# NANO103AE_v1 register map
File version: 1.0
Registers are 32-bit, read-write, reset 0x0 unless marked. A register's access mark holds for its fields unless they carry their own. Offsets are from the block's base; [hi:lo] are bit positions; {n}, {i} and the like mark numbered series.

## UART0 — UART Register Map
Base 0x40050000
Same registers: UART1 0x40150000
0x00 UART_DAT ro reset not defined — UART Receive/Transmit Buffer Register.
  [7:0] DAT — Receive /Transmit Buffer. Write Operation: By writing one byte to this register, the data byte will be stored in transmitter FIFO. The UART Controller will send out the data stored in transmitter FIFO top location through the UART_DAT. Read Operation: By reading this register, the UART will return an 8-bit data received from receiving FIFO.
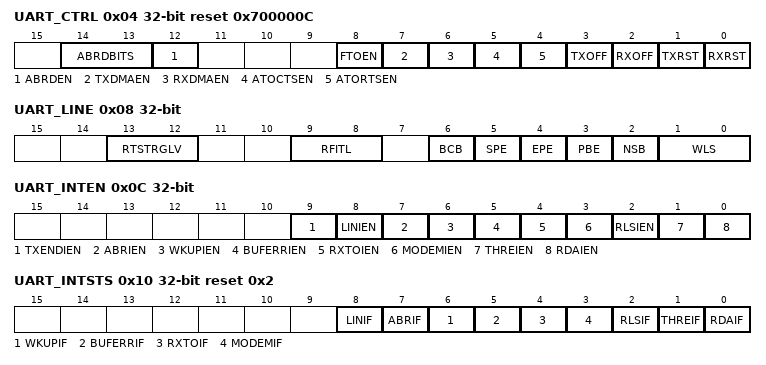
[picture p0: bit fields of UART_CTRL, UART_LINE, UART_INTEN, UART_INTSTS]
0x04 UART_CTRL reset 0x700000C — UART Control Register.
  [14:13] ABRDBITS — Auto-baud Rate Detect Bit Length. Note: The calculation of bit number includes the START bit.
    0=1-bit time from Start bit to the 1st rising edge. The input pattern shall be 0x01; 1=2-bit time from Start bit to the 1st rising edge. The input pattern shall be 0x02; 2=4-bit time from Start bit to the 1st rising edge. The input pattern shall be 0x08; 3=8-bit time from Start bit to the 1st rising edge. The input pattern shall be 0x80
  [12] ABRDEN — Auto-baud Rate Detect EnableBit. Note: When the auto-baud rate detect operation finishes, hardware will clear this bit and the associated interrupt (ABRIF) will be generated (If ABRIEN (UART_INTEN [7]) be enabled).
    0=Auto-baud rate detect function Disabled; 1=Auto-baud rate detect function Enabled
  [8] FTOEN — Frame Time Out Enable Bit. This bit is used to enable the timer counter even the FIFO is still empty.
    0=Frame time out Disabled; 1=Frame time out Enabled
  [7] TXDMAEN — TX DMA Enable Bit. This bit can enable or disable TX DMA service.
    0=TX DMA Disabled; 1=TX DMA Enabled
  [6] RXDMAEN — RX DMA Enable Bit. This bit can enable or disable RX DMA service.
    0=RX DMA Disabled; 1=RX DMA Enabled
  [5] ATOCTSEN — nCTS Auto-flow Control Enable Bit. Note:When nCTS auto-flow is enabled, the UART will send data to external device if nCTS input assert (UART will not send data to device until nCTS is asserted).
    0=nCTS auto-flow control Disabled; 1=nCTS auto-flow control Enabled
  [4] ATORTSEN — nRTS Auto-flow Control Enable Bit. Note: When nRTS auto-flow is enabled, if the number of bytes in the RX FIFO equals the RTSTRGLV (UART_LINE[13:12]), the UART will de-assert nRTS signal.
    0=nRTS auto-flow control Disabled; 1=nRTS auto-flow control Enabled
  [3] TXOFF — Transfer Disable Bit
    0=Transfer Enabled; 1=Transfer Disabled
  [2] RXOFF — Receiver Disable Bit. Note1:In RS-485 NMM mode, user can set this bit to receive data before detecting address byte. Note2: In RS-485 AAD mode, this bit will be setting to "1" automatically. Note3: In RS-485 AUD mode and LIN "break + sync +PID" header mode, hardware will control data automatically, so don't fill any value to this bit.
    0=Receiver Enabled; 1=Receiver Disabled
  [1] TXRST — TX Field Software Reset. When TXRST (UART_CTRL[1]) is set, all the byte in the transmit FIFO and TX internal state machine are cleared. Note: This bit will automatically clear at least 3 UART peripheral clock cycles
    0=No effect; 1=Reset the TX internal state machine and pointers
  [0] RXRST — RX Field Software Reset. When RXRST (UART_CTRL[0]) is set, all the byte in the receiver FIFO and RX internal state machine are cleared. Note: This bit will automatically clear at least 3 UART peripheral clock cycles.
    0=No effect; 1=Reset the RX internal state machine and pointers
0x08 UART_LINE — UART Transfer Line Control Register.
  [13:12] RTSTRGLV — nRTS Trigger Level for Auto-flow Control Use. Note: This field is used for auto nRTS flow control.
    0=nRTS Trigger Level is 1 byte; 1=nRTS Trigger Level is 4 bytes; 2=nRTS Trigger Level is 8 bytes; 3=nRTS Trigger Level is 14 bytes
  [9:8] RFITL — RX FIFO Interrupt Trigger Level. When the number of bytes in the receive FIFO equals the RFITL, the RDAIF will be set (if RDAIEN (UART_INTEN [0]) enabled, and an interrupt will be generated). Note: When operating in IrDA mode or RS-485 mode, the RFITL must be set to "0".
    0=RX FIFO Interrupt Trigger Level is 1 byte; 1=RX FIFO Interrupt Trigger Level is 4 bytes; 2=RX FIFO Interrupt Trigger Level is 8 bytes; 3=RX FIFO Interrupt Trigger Level is 14 bytes
  [6] BCB — Break Control Bit. Note: When this bit is set to logic 1, the serial data output (TX) is forced to the Spacing State (logic 0). This bit acts only on TX line and has no effect on the transmitter logic.
    0=Break Control Disabled; 1=Break Control Enabled
  [5] SPE — Stick Parity Enable Bit. Note: If PBE (UART_LINE[3]) and EPE (UART_LINE[4]) are logic 1, the parity bit is transmitted and checked as logic 0. If PBE (UART_LINE[3]) is 1 and EPE (UART_LINE[4]) is 0 then the parity bit is transmitted and checked as 1.
    0=Stick parity Disabled; 1=Stick parity Enabled
  [4] EPE — Even Parity EnableBit. Note:This bit has effect only when PBE (UART_LINE[3]) is set.
    0=Odd number of logic 1's is transmitted and checked in each word; 1=Even number of logic 1's is transmitted and checked in each word
  [3] PBE — Parity Bit EnableBit. Note: Parity bit is generated on each outgoing character and is checked on each incoming data.
    0=No parity bit generated Disabled; 1=Parity bit generated Enabled
  [2] NSB — Number of "STOP Bit"
    0=One "STOP bit" is generated in the transmitted data; 1=When select 5-bit word length, 1.5 "STOP bit" is generated in the transmitted data. When select 6-, 7- and 8-bit word length, 2 "STOP bit" is generated in the transmitted data
  [1:0] WLS — Word Length Selection. This field sets UART word length.
    {v}={v+5} bits (v=0..3)
0x0C UART_INTEN — UART Interrupt Enable Register.
  [9] TXENDIEN — Transmitter Empty FInterrupt Enable Bit. Note: If the bit is enabled, there is interrupt event when the TXENDF (UART_FIFOSTS[11]) is actived.
    0=Transmit Empty interrupt Disabled; 1=Transmit Empty interrupt Enabled
  [8] LINIEN — LIN Bus Interrupt Enable Bit. Note:This bit is used for LIN function mode.
    0=LIN bus interrupt Disabled; 1=LIN bus interrupt Enabled
  [7] ABRIEN — Auto-baud Rate Interrupt Enable Bit
    0=Auto-baud rate interrupt Disabled; 1=Auto-baud rate interrupt Enabled
  [6] WKUPIEN — Wake-up Interrupt EnableBit. Note: Hardware will clear one of the wake-up status bits in UART_WKUPSTS when the wake-up operation finishes and "system clock" work stable.
    0=Wake-up system function Disabled; 1=Wake-up system function Enabled, when the system is in Power-down mode, one of the wake-up event will wake-up system from Power-down mode
  [5] BUFERRIEN — Buffer Error Interrupt Enable Bit
    0=Buffer error interrupt Disabled; 1=Buffer error interrupt Enabled
  [4] RXTOIEN — RX Time-out Interrupt Enable Bit
    0=RX time-out interrupt Disabled; 1=RX time-outinterrupt Enabled
  [3] MODEMIEN — Modem Status Interrupt Enable Bit
    0=Modem status interrupt Disabled; 1=Modem statusinterrupt Enabled
  [2] RLSIEN — Receive Line Status Interrupt Enable Bit
    0=Receive Line Status interrupt Disabled; 1=Receive Line Status interrupt Enabled
  [1] THREIEN — Transmit Holding Register Empty Interrupt Enable Bit
    0=Transmit holding register empty interrupt Disabled; 1=Transmit holding register empty interrupt Enabled
  [0] RDAIEN — Receive Data Available Interrupt Enable Bit
    0=Receive data available interrupt Disabled; 1=Receive data available interrupt Enabled
0x10 UART_INTSTS reset 0x2 — UART Interrupt Status Register.
  [8] LINIF ro — LIN Interrupt Status Flag (Read Only). This bit is set when the LIN TX header transmitted, RX header received or the SIN does not equal SOUT and if LINIEN(UART_INTEN[8]) is set then the LIN interrupt will be generated. Note1: This bit is read only, but can be cleared by it by writing "1" to BITEF (UART_TRSR[5]), LINTXIF (UART_TRSR[3]) or LINRXIF (UART_TRSR[4]). Note2: This bit is cleared when both the BITEF, LINTXIF and LINRXIF are cleared.
    0=No LIN interrupt is generated; 1=LIN interrupt is generated
  [7] ABRIF ro — Auto-baud Rate Interrupt Status Flag (Read Only). This bit is set when auto-baud rate detection function finished or the auto-baud rate counter was overflow and if ABRIEN (UART_INTEN[7]) is set then the auto-baud rate interrupt will be generated. Note1: This bit is read only, but can be cleared by writing "1" to ABRDTOIF (UART_TRSR[2]) or ABRDIF (UART_TRSR[1]). Note2: This bit is cleared when both the ABRDTOIF and ABRDIF are cleared.
    0=No Auto-Baud Rate interrupt is generated; 1=Auto-Baud Rate interrupt is generated
  [6] WKUPIF ro — Wake-up Interrupt Flag (Read Only). This bit is set if chip wake-up from power-down state by one of UART controller wake-up event. Note1: If WKDATEN (UART_INTEN[6]) is enabled, the wake-up interrupt is generated. Note2: This bit is read only, but can be cleared by writing '1' to one of UART_WKUPSTS[4:0] (THRTOWKSTS or THRWKSTS or CTSWKSTS or DATWKSTS or ADRWKSTS).
    0=Chip stays in power-down state; 1=Chip wake-up from power-down state by one of UART controller wake-up event
  [5] BUFERRIF ro — Buffer Error Interrupt Flag (Read Only). This bit is set when the TX FIFO or RX FIFO overflows (TXOVIF (UART_FIFOSTS[8]) or RXOVIF (UART_FIFOSTS[0]) is set). When BUFERRIF (UART_INTSTS[5])is set, the transfer is not correct. If BFERRIEN (UART_INTEN [5]) is enabled, the buffer error interrupt will be generated. Note:This bit is read only. This bit is cleared if both of RXOVIF(UART_FIFOSTS[0]) and TXOVIF(UART_FIFOSTS[8]) are cleared to 0 by writing 1 to RXOVIF(UART_FIFOSTS[0]) and TXOVIF(UART_FIFOSTS[8]).
    0=No buffer error interrupt flag is generated; 1=Buffer error interrupt flag is generated
  [4] RXTOIF ro — Rime-out Interrupt Flag (Read Only). This bit is set when the RX FIFO is not empty and no activities occurred in the RX FIFO and the time-out counter equal to TOIC. If RXTOIEN (UART_INTEN [4]) is enabled, the Tout interrupt will be generated. Note: This bit is read only and user can read UART_DAT (RX is in active) to clear it
    0=No Time-out interrupt flag is generated; 1=Time-out interrupt flag is generated
  [3] MODEMIF ro — MODEM Interrupt Flag (Read Only) Channel. Note: This bit is read only and reset to 0 when bit CTSDETF is cleared by a write 1 on CTSDETF(UART_MODEM[18]).
    0=No Modem interrupt flag is generated; 1=Modem interrupt flag is generated
  [2] RLSIF ro — Receive Line Interrupt Flag (Read Only). This bit is set when the RX receive data have parity error, frame error or break error (at least one of 3 bits, BIF(UART_FIFOSTS[6]), FEF(UART_FIFOSTS[5]) and PEF(UART_FIFOSTS[4]), is set). If RLSIEN (UART_INTEN [2]) is enabled, the RLS interrupt will be generated. Note2: This bit is read only and reset to 0 when all bits of BIF (UART_FIFOSTS[6]), FEF(UART_FIFOSTS[5]) and PEF(UART_FIFOSTS[4]) are cleared. Note3: In RS-485 function mode, this bit is read only and reset to 0 when all bits of BIF (UART_FIFOSTS[6]) , FEF(UART_FIFOSTS[5]) and PEF(UART_FIFOSTS[4]) and ADDRDETF (UART_TRSR[0]) are cleared.
    0=No RLS interrupt flag is generated; 1=RLS interrupt flag is generated
  [1] THREIF ro — Transmit Holding Register Empty Interrupt Flag (Read Only). This bit is set when the last data of TX FIFO is transferred to Transmitter Shift Register. If THREIEN (UART_INTEN[1]) is enabled, the THRE interrupt will be generated. Note: This bit is read only and it will be cleared when writing data into UART_DAT (TX FIFO not empty)
    0=No THRE interrupt flag is generated; 1=THRE interrupt flag is generated
  [0] RDAIF ro — Receive Data Available Interrupt Flag (Read Only). When the number of bytes in the RX FIFO equals the RFITL then the RDAIF(UART_INTSTS[0]) will be set. If RDAIEN (UART_INTEN [0]) is enabled, the RDA interrupt will be generated. Note: This bit is read only and it will be cleared when the number of unread bytes of RX FIFO drops below the threshold level (RFITL(UART_LINE[9:8])
    0=No RDA interrupt flag is generated; 1=RDA interrupt flag is generated
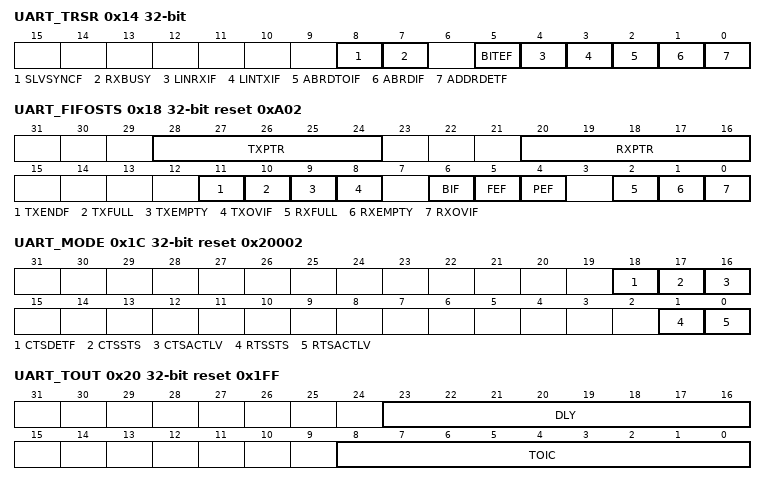
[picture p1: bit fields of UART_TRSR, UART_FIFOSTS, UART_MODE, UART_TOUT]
0x14 UART_TRSR — UART Transfer Status Register.
  [8] SLVSYNCF ro — LIN RX SYNC Error Flag (Read Only). This bit is set to logic "1" when LIN received incorrect SYNC field. User can choose the header by setting LINHSEL (UART_ATLCTL[5:4]) register. Note: This bit is read only, but can be cleared by writing "1" to LINRXIF.
    0=No LIN Rx sync error is generated; 1=LIN Rx sync error is generated
  [7] RXBUSY ro — Receive Busy Status(Read Only). Note: The user can use this to check the busy status in receiver mode. If the user wants to enter power down, this bit shall be confirm in Idle state and there is 2 UART clock latency for receiver pin.
    0=The receiver machine stays in idle state; 1=The receiver machine stays in no Idle state
  [5] BITEF ro — Bit Error Detect Status Flag (Read Only). At TX transfer state, hardware will monitoring the bus state, if the input pin (SIN) state is not equal to the output pin (SOUT) state, BITEF will be set. When occur bit error, hardware will generate an interrupt to CPU (LININT).
    0=No Bit error interrupt is generated; 1=Bit error interrupt is generated
  [4] LINRXIF ro — LIN RX Interrupt Flag (Read Only). This bit is set to logic "1" when received LIN header field. The header may be "break field" or "break field + sync field" or "break field + sync field + PID field", and it can be choose by setting LINHSEL (UART_ATLCTL[5:4]) register. Note: This bit is read only, but can be cleared by writing "1" to it.
    0=No LIN Rx interrupt is generated; 1=LIN Rx interrupt is generated
  [3] LINTXIF ro — LIN TX Interrupt Flag (Read Only). This bit is set to logic "1" when LIN transmitted header field. The header may be "break field" or "break field + sync field" or "break field + sync field + PID field", it can be choose by setting LINHSEL (UART_ATLCTL[5:4]) register. Note: This bit is read only, but can be cleared by writing "1" to it.
    0=No LIN Transmit interrupt is generated; 1=LIN Transmit interrupt is generated
  [2] ABRDTOIF ro — Auto-baud Rate Time-out Interrupt(Read Only). Note1:This bit is set to logic "1" in Auto-baud Rate Detect mode and the baud rate counter is overflow. Note2: This bit is read only, but can be cleared by writing "1" to it.
    0=Auto-baud rate counter is underflow; 1=Auto-baud rate counter is overflow
  [1] ABRDIF ro — Auto-baud Rate Interrupt (Read Only). This bit is set to logic "1" when auto-baud rate detect function finished. Note: This bit is read only, but can be cleared by writing "1" to it.
    0=No Auto- Baud Rate interrupt is generated; 1=Auto-Baud Rate interrupt is generated
  [0] ADDRDETF ro — RS-485 Address Byte Detection Status Flag (Read Only). Note1: This field is used for RS-485 function mode and ADDRDEN (UART_ATLCTL[19]) is set to 1 to enable Address detection mode . Note2: This bit is read only, but can be cleared by writing '1' to it.
    0=Receiver detects a data that is not an address bit (bit 9 ='0'); 1=Receiver detects a data that is an address bit (bit 9 ='1')
0x18 UART_FIFOSTS reset 0xA02 — UART FIFO Status Register.
  [28:24] TXPTR ro — TX-fIFO Pointer (Read Only). This field indicates the TX FIFO Buffer Pointer. When CPU writes one byte into UART_DAT, TXPTR increases one. When one byte of TX FIFO is transferred to Transmitter Shift Register, TXPTR decreases one. The Maximum value shown in TXPTR is 15. When the using level of TX FIFO Buffer equal to 16, the TXFULL bit is set to 1 and TXPTR will show 0. As one byte of TX FIFO is transferred to Transmitter Shift Register, the TXFULL bit is cleared to 0 and TXPTR will show 15.
  [20:16] RXPTR ro — RX FIFO Pointer (Read Only). This field indicates the RX FIFO Buffer Pointer. When UART receives one byte from external device, RXPTR increases one. When one byte of RX FIFO is read by CPU, RXPTR decreases one. The Maximum value shown in RXPTR is 15. When the using level of RX FIFO Buffer equal to 16, the RXFULL bit is set to 1 and RXPTR will show 0. As one byte of RX FIFO is read by CPU, the RXFULL bit is cleared to 0 and RXPTR will show 15.
  [11] TXENDF ro — Transmitter Empty Flag (Read Only). This bit is set by hardware when TX FIFO (UART_DAT) is empty and the STOP bit of the last byte has been transmitted. Note:This bit is cleared automatically when TX FIFO is not empty or the last byte transmission has not completed.
    0=TX FIFO is not empty or the STOP bit of the last byte has been not transmitted; 1=TX FIFO is empty and the STOP bit of the last byte has been transmitted
  [10] TXFULL ro — Transmitter FIFO Full (Read Only). This bit indicates TX FIFO full or not. Note:This bit is set when the number of usage in TX FIFO Buffer is equal to 16, otherwise is cleared by hardware.
    0=TX FIFO is not full; 1=TX FIFO is full
  [9] TXEMPTY ro — Transmitter FIFO Empty (Read Only). This bit indicates TX FIFO empty or not. Note: When the last byte of TX FIFO has been transferred to Transmitter Shift Register, hardware sets this bit high. It will be cleared when writing data into DAT (TX FIFO not empty).
    0=TX FIFO is not empty; 1=TX FIFO is empty
  [8] TXOVIF ro — TX Overflow Error Interrupt Status Flag (Read Only). If TX FIFO (UART_DAT) is full, an additional write to UART_DAT will cause this bit to logic 1. Note:This bit is read only, but can be cleared by writing "1" to it.
    0=TX FIFO did not overflow; 1=TX FIFO overflowed
  [6] BIF ro — Break Interrupt Flag( Read Only). This bit is set to logic 1 whenever the received data input (RX) is held in the "spacing state" (logic 0) for longer than a full word transmission time (that is, the total time of "start bit" + data bits + parity + stop bits). Note: This bit is read only, but can be cleared by writing '1' to it.
    0=No Break interrupt is generated; 1=Break interrupt is generated
  [5] FEF ro — Framing Error Flag (Read Only). This bit is set to logic 1 whenever the received character does not have a valid "stop bit" (that is, the stop bit following the last data bit or parity bit is detected as logic 0). Note: This bit is read only, but can be cleared by writing '1' to it.
    0=No framing error is generated; 1=Framing error is generated
  [4] PEF ro — Parity Error State Status Flag (Read Only). This bit is set to logic 1 whenever the received character does not have a valid "parity bit". Note: This bit is read only, but can be cleared by writing '1' to it.
    0=No parity error is generated; 1=Parity error is generated
  [2] RXFULL ro — Receiver FIFO Full (Read Only). This bit initiates RX FIFO full or not. Note: This bit is set when the number of usage in RX FIFO Buffer is equal to 16, otherwise is cleared by hardware.
    0=RX FIFO is not full; 1=RX FIFO is full
  [1] RXEMPTY ro — Receiver FIFO Empty (Read Only). This bit initiate RX FIFO empty or not. Note: When the last byte of RX FIFO has been read by CPU, hardware sets this bit high. It will be cleared when UART receives any new data.
    0=RX FIFO is not empty; 1=RX FIFO is empty
  [0] RXOVIF ro — RX Overflow Error Status Flag (Read Only). This bit is set when RX FIFO overflow. If the number of bytes of received data is greater than RX_FIFO (UART_DAT) size, this bit will be set. Note:This bit is read only, but can be cleared by writing "1" to it.
    0=RX FIFO is not overflow; 1=RX FIFO is overflow
0x1C UART_MODE reset 0x20002 — UART Modem Control Status Register.
  [18] CTSDETF ro — Detect nCTS State Change Flag (Read Only). This bit is set whenever nCTS input has change state, and it will generate Modem interrupt to CPU when MODEMIEN (UART_INTEN[3]). Note: This bit is read only, but it can be cleared by writing "1" to it.
    0=nCTS input has not change state; 1=nCTS input has change state
  [17] CTSSTS ro — nCTS Pin Status (Read Only). This bit mirror from nCTS pin input of voltage logic status. Note: This bit echoes when UART Controller peripheral clock is enabled, and nCTS multi-function port is selected.
    0=nCTS pin input is low level voltage logic state; 1=nCTS pin input is high level voltage logic state
  [16] CTSACTLV — nCTS Trigger Level. This bit defines the active level state of nCTS pin input.
    0=nCTS pin input is high level active; 1=nCTS pin input is low level active. (Default)
  [1] RTSSTS ro — nRTS Pin State (Read Only). This bit mirror from nRTS pin output of voltage logic status.
    0=nRTS pin output is low level voltage logic state; 1=nRTS pin output is high level voltage logic state
  [0] RTSACTLV — nRTS Pin Active Level. This bit defines the active level state of nRTS pin output.
    0=nRTS pin output is high level active; 1=nRTS pin output is low level active. (Default)
0x20 UART_TOUT reset 0x1FF — UART Time-Out Control Register.
  [23:16] DLY — TX Delay Time Value. This field is used to programming the transfer delay time between the last stop bit and next start bit. The unit is bit time. Note1: Fill all "0" to this field indicates to disable this function. Note2: The real delay value is DLY. Note3:The counting clock is baud rate clock.
  [8:0] TOIC — Time-out Comparator. Note1: Fill all "0" to this field indicates to disable this function. Note2: The real time-out value is TOIC + 1. Note3: The counting clock is baud rate clock. Note4: The UART data format is start bit + 8 data bits + parity bit + stop bit, although software can configure this field by any value but it is recommend to fill this field great than 0xA.
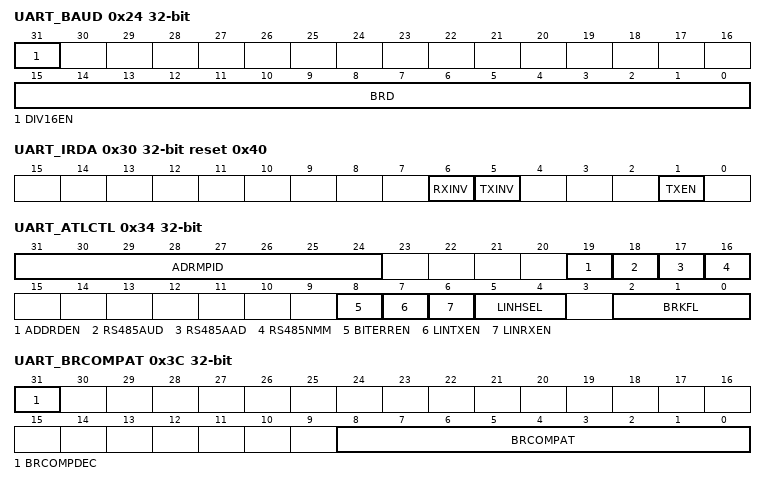
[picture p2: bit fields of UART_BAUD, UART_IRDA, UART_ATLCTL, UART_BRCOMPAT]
0x24 UART_BAUD — UART Baud Rate Divisor Register.
  [31] DIV16EN — Divider 16 Enable Control. Note: In IrDA mode, this bit must clear to "0".
    0=The equation of baud rate is UART_CLK / [(BRD+1)]; 1=The equation of baud rate is UART_CLK / [16 * (BRD+1)]
  [15:0] BRD — Baud Rate Divider. The field indicates the baud rate divider. This filed is used in baud rate calculation. The detail description is shown inUART Controller Baud Rate Generation.
0x30 UART_IRDA reset 0x40 — UART IrDA Control Register.
  [6] RXINV — IrDA Inverse Receive Input Signal
    0=None inverse receiving input signal; 1=Inverse receiving input signal. (Default)
  [5] TXINV — IrDA Inverse Transmitting Output Signal
    0=None inverse transmitting signal. (Default); 1=Inverse transmitting output signal
  [1] TXEN — IrDA Receiver/Transmitter Selection Enable Bit
    0=IrDA Transmitter Disabled and Receiver Enabled. (Default); 1=IrDA Transmitter Enabled and Receiver Disabled
0x34 UART_ATLCTL — UART Alternate Control State Register.
  [31:24] ADRMPID — Address / PID Match Value Register. When in the RS-485 Function Mode, this field contains the RS-485 address match values. When in the LIN Function mode, this field contains the LIN protected identifier field, software fills ID0~ID5 (PID [5:0]), hardware will calculate P0 and P1. . Note: This field is used for RS-485 auto address detection mode or used for LIN protected identifier field (PID).
  [19] ADDRDEN — RS-485 Address Detection Enable Bit. This bit is used to enable RS-485 Address Detection mode. Note: This bit is used for RS-485 any operation mode.
    0=Address detection mode Disabled; 1=Address detection mode Enabled
  [18] RS485AUD — RS-485 Auto Direction Function (AUD). Note: It can be active with RS485AAD or RS485NMM operation mode.
    0=RS-485 Auto Direction Operation function (AUD) Disabled; 1=RS-485 Auto Direction Operation function (AUD) Enabled
  [17] RS485AAD — RS-485 Auto Address Detection Operation Mode (AAD). Note: It cannot be active with RS485NMM operation mode.
    0=RS-485 Auto Address Detection Operation mode (AAD) Disabled; 1=RS-485 Auto Address Detection Operation mode (AAD) Enabled
  [16] RS485NMM — RS-485 Normal Multi-drop Operation Mode (NMM). Note: It cannot be active with RS-485_AAD operation mode.
    0=RS-485 Normal Multi-drop Operation mode (NMM) Disabled; 1=RS-485 Normal Multi-drop Operation mode (NMM) Enabled
  [8] BITERREN — Bit Error Detect EnableBit
    0=Bit error detection Disabled; 1=Bit error detection Enabled
  [7] LINTXEN — LIN TX Header Trigger EnableBit. The LIN TX header can be "break field" or "break and sync field" or "break, sync and frame ID field", it is depend on setting LINHSEL (UART_ATLCTL[5:4]). Note1: This bit will be cleared automatically and generate a interrupt to CPU (LININT). Note2:When transmitter header field (it may be "break" or "break + sync" or "break + sync + frame ID" selected by LINHSEL (UART_ATLCTL[5:4]) field) transfer operation finished, this bit will be cleared automatically. Note3: If user wants to receive transmit data, it recommended to enable LINRXEN bit.
    0=Send LIN TX header Disabled; 1=Send LIN TX header Enabled
  [6] LINRXEN — LIN RX Enable Control. When LIN RX mode enabled and received a break field or sync field or PID field (Select by LIN_Header_SEL), the controller will generator a interrupt to CPU (LININT)
    0=LIN RX mode Disabled; 1=LIN RX mode Enabled
  [5:4] LINHSEL — LIN Header Selection
    0=The LIN header includes "break field"; 1=The LIN header includes "break field + sync field"; 2=The LIN header includes "break field + sync field + PID field"
  [2:0] BRKFL — LIN TX Break Field Count. The field contains 3-bit LIN TX break field count. Note: The break field length is BRKFL + 8.
0x38 UART_FUNCSEL — UART Function Select Register.
  [1:0] FUNCSEL — Function Selection
    0=UART function mode; 1=LIN function mode; 2=IrDA function mode; 3=RS-485 function mode
0x3C UART_BRCOMPAT — UART Baud Rate Compensation Register.
  [31] BRCOMPDEC — Baud Rate Compensation Decrease
    0=Positive (increase one module clock) compensation for each compensated bit; 1=Negative (decrease one module clock) compensation for each compensated bit
  [8:0] BRCOMPAT — Baud Rate Compensation Patten. These 9bits are used to define the relative bit is compensated or not. BRCOMPAT[7:0] is used to define the compensation of D[7:0] and BRCOMPAT{[8] is used to define the parity bit.
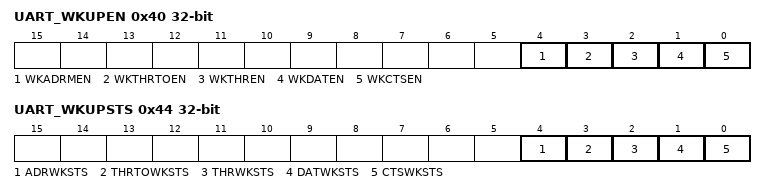
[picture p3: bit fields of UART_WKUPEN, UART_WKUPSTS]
0x40 UART_WKUPEN — UART Wake-up Enable Register.
  [4] WKADRMEN — RS-485 Address Match Wake-up Enable Bit
    0=RS-485 ADD mode address match wake-up function Disabled; 1=RS-485 AAD mode address match wake-up function Enabled when the system is in power-down mode
  [3] WKTHRTOEN — FIFO Threshold Reach Time Out Wake-up Enable Bit. Note: It is suggest the function is enabled when the WKTHREN (UART_WKUPEN[2]) is set to 1.
    0=Received FIFO threshold no reach and time out wake-up function Disabled; 1=Received FIFO threshold no reach and time out wake-up function Enabled when the system is in power-down mode
  [2] WKTHREN — FIFO Threshold Reach Wake-up Enable Bit. Note: It is suggest the function is enabled in UART mode and the UART clock is selected in 32K.
    0=Received FIFO threshold reach wake-up function Disabled; 1=Received FIFO threshold reach wake-up function Enabled when the system is in power-down mode
  [1] WKDATEN — Incoming Data Wake-up Enable Bit. Note: Hardware will clear this bit when the incoming data wake-up operation finishes and "system clock" work stable.
    0=Incoming data wake-up function Disabled; 1=Incoming data wake-up function Enabled when the system is in power-down mode, incoming data will wake-up system from power-down mode
  [0] WKCTSEN — CTSn Wake-up Enable Bit. When the system is in power-down mode, an external nCTS change will wake-up system from power-down mode.
    0=nCTS wake-up function Disabled; 1=nCTS wake-up function Enabled
0x44 UART_WKUPSTS — UART Wake-up Status Register.
  [4] ADRWKSTS ro — RS-485 Address Byte Detection Wake-up Flag (Read Only). Note1: If WKADRMEN (UART_WKUPEN[4])is enabled, the wake-up function is generated. Note2: This field is used for RS-485 function mode and ADDRDEN (UART_ATLCTL[19]) is set to 1 to enable Address detection mode . Note2: This bit is read only, but can be cleared by writing '1' to it.
    0=Chip stays in power-down state; 1=Chip wake-up from power-down state by Receiver detects a data that is an address bit (bit 9 ='1')
  [3] THRTOWKSTS ro — Threshold Wake-up Time Out Flag (Read Only). Note1: If WKTHRTOEN (UART_ WKUPEN [3])is enabled, the wake-up function is generated. Note2: This bit is read only, but can be cleared by writing '1' to it.
    0=Chip stays in power-down state; 1=Chip wake-up from power-down state by FIFO threshold time out wake-up
  [2] THRWKSTS ro — Threshold Wake-up Flag (Read Only). Note1: If WKTHREN (UART_ WKUPEN [2])is enabled, the wake-up function is generated. Note2: This bit is read only, but can be cleared by writing '1' to it.
    0=Chip stays in power-down state; 1=Chip wake-up from power-down state by FIFO threshold wake-up
  [1] DATWKSTS ro — Data Wake-up Flag (Read Only). This bit is set if chip wake-up from power-down state by data wake-up. Note1: If WKDATEN (UART_ WKUPEN [1]) is enabled, the wake-up function is generated. Note2: This bit is read only, but can be cleared by writing '1' to it
    0=Chip stays in power-down state; 1=Chip wake-up from power-down state by data wake-up
  [0] CTSWKSTS ro — nCTS Wake-up Flag (Read Only). Note1: If WKCTSEN (UART_ WKUPEN [0])is enabled, the wake-up function is generated. Note2: This bit is read only, but can be cleared by writing '1' to it.
    0=Chip stays in power-down state; 1=Chip wake-up from power-down state by nCTS wake-up
